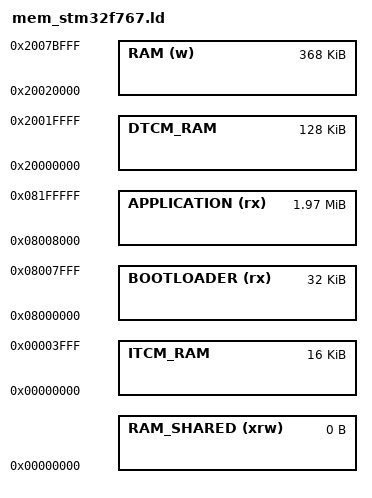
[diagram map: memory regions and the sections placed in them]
MEMORY
{
  RAM (w)          : ORIGIN = 0x20020000, LENGTH = 368K
  RAM_SHARED (xrw) : ORIGIN = 0, LENGTH = 0
  DTCM_RAM         : ORIGIN = 0x20000000, LENGTH = 128K
  ITCM_RAM         : ORIGIN = 0x00000000, LENGTH = 16K
  BOOTLOADER (rx)  : ORIGIN = 0x08000000, LENGTH = 32K
  APPLICATION (rx) : ORIGIN = 0x08008000, LENGTH = 2048K - 32K
}

_flash_start = ORIGIN(BOOTLOADER);
_flash_end = ORIGIN(APPLICATION) + LENGTH(APPLICATION);
_application_start = ORIGIN(APPLICATION);
_application_end = ORIGIN(APPLICATION) + LENGTH(APPLICATION);
